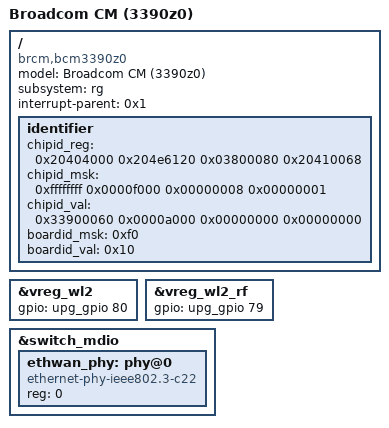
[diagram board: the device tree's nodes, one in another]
/dts-v1/;

/ {
	model = "Broadcom CM (3390z0)";
	compatible = "brcm,bcm3390z0", "brcm,brcmstb";
	subsystem = "rg";
	#address-cells = <0x2>;
	#size-cells = <0x2>;
	interrupt-parent = <0x1>;

	identifier {
			    /* chip id    mfg id     a/c pwr    don't park */
		chipid_reg = < 0x20404000 0x204e6120 0x03800080 0x20410068 >;
		chipid_msk = < 0xffffffff 0x0000f000 0x00000008 0x00000001 >;
		chipid_val = < 0x33900060 0x0000a000 0x00000000 0x00000000 >;
			     /* SV   */
		boardid_msk = < 0xf0 >;
		boardid_val = < 0x10 >;
	};
};

/include/ "rg.3390b0-bolt.dtsi"
/include/ "rg.3390z0-bolt.dtsi"
/include/ "rg.3390-base.dtsi"
/include/ "rg.3390-wifi.dtsi"
/include/ "rg.3390-ethwan.dtsi"

/********************************************************************
 * any nodes that appear below are platform specific additions and
 * replacements.
 * The dtc will add or replace any properties in the nodes
 * below to the same nodes that appear in include files above.
 * If the property does not exist in the node above it will be added.
 * If the property does exist it will replace it.
 ********************************************************************/
&vreg_wl2 {
	gpio = <&upg_gpio 80 0>;
};

&vreg_wl2_rf {
	gpio = <&upg_gpio 79 0>;
};

&switch_mdio {
	ethwan_phy: phy@0 {	/* external bcm54210 */
		compatible = "ethernet-phy-ieee802.3-c22";
		reg = <0>;
	};
};
